VERSION ""

NS_ :

BS_:

BU_:

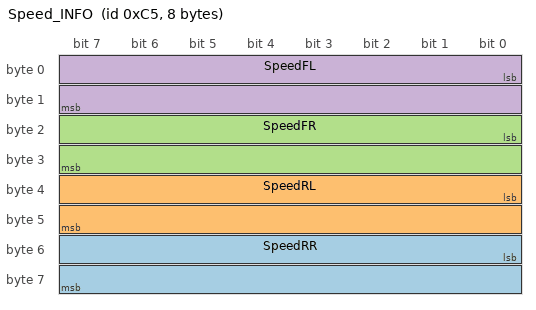
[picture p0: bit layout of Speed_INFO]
BO_ 197 Speed_INFO: 8 Vector__XXX
 SG_ SpeedRR : 48|16@1- (0.01,0) [-327.68|327.67] "km/h" Vector__XXX
 SG_ SpeedRL : 32|16@1- (0.01,0) [-327.68|327.67] "km/h" Vector__XXX
 SG_ SpeedFR : 16|16@1- (0.01,0) [-327.68|327.67] "km/h" Vector__XXX
 SG_ SpeedFL : 0|16@1- (0.01,0) [-327.68|327.67] "km/h" Vector__XXX

BA_DEF_  "BusType" STRING ;
BA_DEF_DEF_  "BusType" "CAN";
